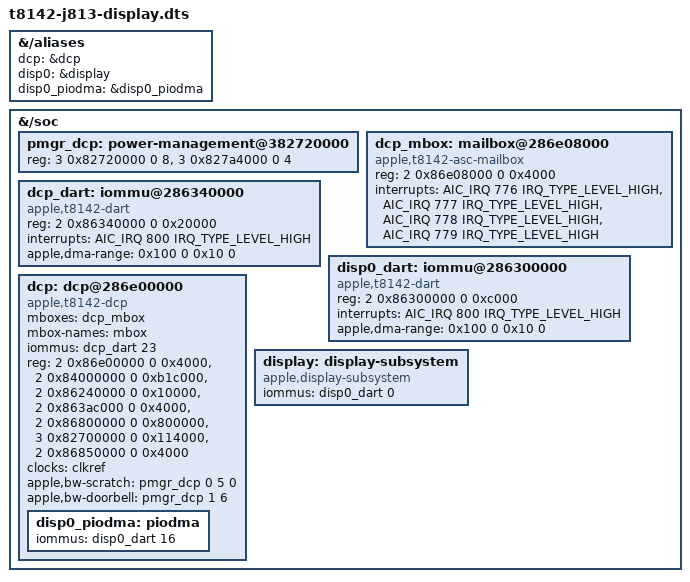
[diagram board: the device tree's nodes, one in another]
// SPDX-License-Identifier: GPL-2.0+ OR MIT
#include "t8142-j813-input.dts"

/* RAM bring-up: preserve the live iBoot display generation. Resources and
 * DART streams were read from the M5 on 2026-09-11. The boot preflight must
 * verify DISP_CPU is on and preserve inherited DMA mappings before loading
 * appledrm. No reset or unqualified power controller is introduced here.
 */
&{/aliases} {
	dcp = &dcp;
	disp0 = &display;
	disp0_piodma = &disp0_piodma;
};

&{/soc} {
	/* Native T8142 PMC group 34 uses ADT reg[47] + 0x700000.
	 * DISP_INT has BWR agent 0 and DISP_INT_DCP has boost agent 0.
	 * Native offsets are 0x20000 + agent*0x4000 and
	 * 0xa4000 + agent*0x4000, respectively.
	 */
	pmgr_dcp: power-management@382720000 {
		reg = <3 0x82720000 0 8>, <3 0x827a4000 0 4>;
		reg-names = "dcp-bw-scratch", "dcp-bw-doorbell";
		#apple,bw-scratch-cells = <3>;
		#apple,bw-doorbell-cells = <2>;
	};

	dcp_mbox: mailbox@286e08000 {
		compatible = "apple,t8142-asc-mailbox", "apple,asc-mailbox-v4";
		reg = <2 0x86e08000 0 0x4000>;
		interrupts = <AIC_IRQ 776 IRQ_TYPE_LEVEL_HIGH>,
			     <AIC_IRQ 777 IRQ_TYPE_LEVEL_HIGH>,
			     <AIC_IRQ 778 IRQ_TYPE_LEVEL_HIGH>,
			     <AIC_IRQ 779 IRQ_TYPE_LEVEL_HIGH>;
		interrupt-names = "send-empty", "send-not-empty",
				  "recv-empty", "recv-not-empty";
		#mbox-cells = <0>;
	};

	dcp_dart: iommu@286340000 {
		compatible = "apple,t8142-dart", "apple,t8110-dart";
		reg = <2 0x86340000 0 0x20000>;
		interrupts = <AIC_IRQ 800 IRQ_TYPE_LEVEL_HIGH>;
		#iommu-cells = <1>;
		apple,dma-range = <0x100 0 0x10 0>;
	};

	disp0_dart: iommu@286300000 {
		compatible = "apple,t8142-dart", "apple,t8110-dart";
		reg = <2 0x86300000 0 0xc000>;
		interrupts = <AIC_IRQ 800 IRQ_TYPE_LEVEL_HIGH>;
		#iommu-cells = <1>;
		apple,dma-range = <0x100 0 0x10 0>;
	};

	dcp: dcp@286e00000 {
		compatible = "apple,t8142-dcp", "apple,dcp";
		phandle = <&dcp>;
		mboxes = <&dcp_mbox>;
		mbox-names = "mbox";
		iommus = <&dcp_dart 23>;
		reg = <2 0x86e00000 0 0x4000>,
		      <2 0x84000000 0 0xb1c000>,
		      <2 0x86240000 0 0x10000>,
		      <2 0x863ac000 0 0x4000>,
		      <2 0x86800000 0 0x800000>,
		      <3 0x82700000 0 0x114000>,
		      <2 0x86850000 0 0x4000>;
		reg-names = "coproc", "disp-0", "disp-1", "disp-2",
			    "disp-3", "disp-4", "iop-vbar";
		clocks = <&clkref>;
		apple,bw-scratch = <&pmgr_dcp 0 5 0>;
		apple,bw-doorbell = <&pmgr_dcp 1 6>;
		#address-cells = <2>;
		#size-cells = <2>;

		disp0_piodma: piodma {
			iommus = <&disp0_dart 16>;
			phandle = <&disp0_piodma>;
		};
	};

	display: display-subsystem {
		compatible = "apple,display-subsystem";
		iommus = <&disp0_dart 0>;
		phandle = <&display>;
	};
};
